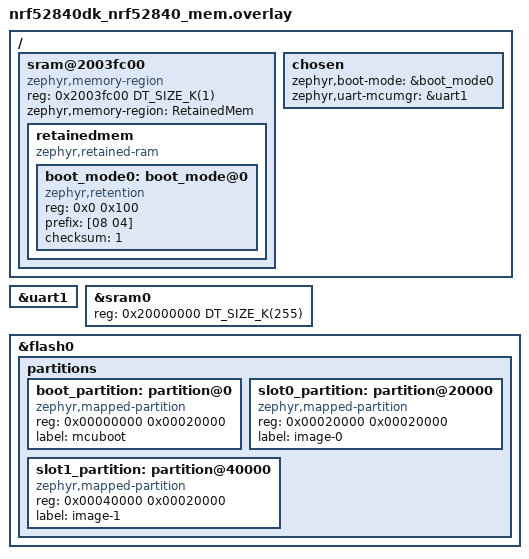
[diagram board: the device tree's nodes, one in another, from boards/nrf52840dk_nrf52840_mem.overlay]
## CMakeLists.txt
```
#
# Copyright (c) 2023 Nordic Semiconductor ASA
#
# SPDX-License-Identifier: Apache-2.0
#

cmake_minimum_required(VERSION 3.28.0)
find_package(Zephyr REQUIRED HINTS $ENV{ZEPHYR_BASE})
project(mcuboot_recovery_retention)

if(NOT (DEFINED SYSBUILD))
  message(FATAL_ERROR "This test must be built with sysbuild.")
endif()

FILE(GLOB app_sources
  src/*.c
)

target_sources(app PRIVATE ${app_sources})
```

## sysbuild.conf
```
SB_CONFIG_BOOTLOADER_MCUBOOT=y
SB_CONFIG_PARTITION_MANAGER=n
```

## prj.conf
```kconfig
#
# Copyright (c) 2023 Nordic Semiconductor ASA
#
# SPDX-License-Identifier: Apache-2.0
#
CONFIG_RETAINED_MEM=y
CONFIG_RETENTION=y
CONFIG_BOOT_MODE=y
CONFIG_REBOOT=y
CONFIG_LOG=y
```

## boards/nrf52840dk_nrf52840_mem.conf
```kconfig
#
# Copyright (c) 2023 Nordic Semiconductor ASA
#
# SPDX-License-Identifier: Apache-2.0
#
CONFIG_RETAINED_MEM_NRF_GPREGRET=n
CONFIG_RETAINED_MEM_ZEPHYR_RAM=y
```

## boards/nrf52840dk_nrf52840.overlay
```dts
/* SPDX-License-Identifier: Apache-2.0 */

/ {
	chosen {
		zephyr,uart-mcumgr = &uart1;
	};
};

&uart1 {
	status = "okay";
};

/delete-node/ &boot_partition;
/delete-node/ &slot0_partition;
/delete-node/ &slot1_partition;

&flash0 {
	partitions {
		boot_partition: partition@0 {
			compatible = "zephyr,mapped-partition";
			reg = <0x00000000 0x00020000>;
			label = "mcuboot";
		};

		slot0_partition: partition@20000 {
			compatible = "zephyr,mapped-partition";
			reg = <0x00020000 0x00020000>;
			label = "image-0";
		};

		slot1_partition: partition@40000 {
			compatible = "zephyr,mapped-partition";
			reg = <0x00040000 0x00020000>;
			label = "image-1";
		};
	};
};
```

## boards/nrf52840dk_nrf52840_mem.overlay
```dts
/* SPDX-License-Identifier: Apache-2.0 */

/ {
	sram@2003fc00 {
		compatible = "zephyr,memory-region", "mmio-sram";
		reg = <0x2003fc00 DT_SIZE_K(1)>;
		zephyr,memory-region = "RetainedMem";
		status = "okay";

		retainedmem {
			compatible = "zephyr,retained-ram";
			#address-cells = <1>;
			#size-cells = <1>;
			status = "okay";

			boot_mode0: boot_mode@0 {
				compatible = "zephyr,retention";
				reg = <0x0 0x100>;
				prefix = [08 04];
				checksum = <1>;
				status = "okay";
			};
		};
	};

	chosen {
		zephyr,boot-mode = &boot_mode0;
		zephyr,uart-mcumgr = &uart1;
	};
};

&uart1 {
	status = "okay";
};

/delete-node/ &gpregret1;
/delete-node/ &gpregret2;
/delete-node/ &boot_partition;
/delete-node/ &slot0_partition;
/delete-node/ &slot1_partition;

&sram0 {
	reg = <0x20000000 DT_SIZE_K(255)>;
};

&flash0 {
	partitions {
		boot_partition: partition@0 {
			compatible = "zephyr,mapped-partition";
			reg = <0x00000000 0x00020000>;
			label = "mcuboot";
		};

		slot0_partition: partition@20000 {
			compatible = "zephyr,mapped-partition";
			reg = <0x00020000 0x00020000>;
			label = "image-0";
		};

		slot1_partition: partition@40000 {
			compatible = "zephyr,mapped-partition";
			reg = <0x00040000 0x00020000>;
			label = "image-1";
		};
	};
};
```

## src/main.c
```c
/*
 * Copyright (c) 2023 Nordic Semiconductor ASA
 *
 * SPDX-License-Identifier: Apache-2.0
 */

#include <stdint.h>
#include <zephyr/sys/reboot.h>
#include <zephyr/bootmode.h>
#include <zephyr/kernel.h>
#include <stdio.h>

int main(void)
{
	printf("Waiting...\n");
	k_sleep(K_SECONDS(1));

	int rc = bootmode_set(BOOT_MODE_TYPE_BOOTLOADER);

	if (rc == 0) {
		sys_reboot(SYS_REBOOT_WARM);
	} else {
		printf("Error, failed to set boot mode: %d\n", rc);
	}

	return 0;
}
```
